# STM32H7RSxx register map
File version: 0.2
CPU: CM7 r0p1, little endian, MPU, FPU, 4 interrupt priority bits
Registers are 32-bit, read-write, reset 0x0 unless marked. A register's access mark holds for its fields unless they carry their own. Offsets are from the block's base; [hi:lo] are bit positions; 'fields as' and 'values as' point back to an identical list; <NAME> marks a mode.

## XSPI1 — XSPI register block
Base 0x52000500
Same registers: XSPI2 0x5200A000, XSPIM 0x5200B400
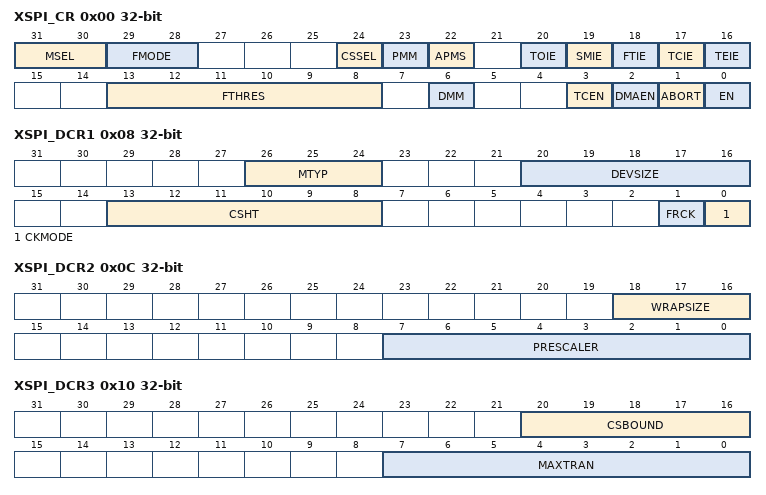
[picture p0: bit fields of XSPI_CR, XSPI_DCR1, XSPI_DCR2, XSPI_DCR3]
0x00 XSPI_CR — XSPI control register
  [31:30] MSEL — Flash select These bits select the memory to be addressed in single-, dual-, quad -or octal-SPI mode in single‑memory configuration (when DMM = 0). - when in quad-SPI mode: - when in octal-SPI mode or dual-quad configuration: 0x: data exchanged over IO[7:0] 1x: data exchanged over IO[15:8] These bits are ignored when in dual-octal configuration (data on 8 bits and DMM = 1) or 16‑bit configuration (data exchanged over IO[15:0]). Note: This bit is mirrored in bit 7. Note: This bitfield can be modified only when BUSY = 0.
    0=data exchanged over IO[3:0]; 1=data exchanged over IO[7:4]; 2=data exchanged over IO[11:8]; 3=data exchanged over IO[15:12]
  [29:28] FMODE — Functional mode This field defines the XSPI functional mode of operation. If DMAEN = 1 already, then the DMA controller for the corresponding channel must be disabled before changing the FMODE[1:0] value. If FMODE[1:0] and FTHRES[4:0] are wrongly updated while DMAEN = 1, the DMA request signal automatically goes to inactive state. Note: This bitfield can be modified only when BUSY = 0.
    0=indirect-write mode; 1=indirect-read mode; 2=automatic status-polling mode; 3=memory-mapped mode
  [24] CSSEL — chip select selection This bit indicates if the XSPI must activate NCS1 or NCS2. Note: This bit can be modified only when BUSY = 0.
    0=NCS1 active; 1=NCS2 active
  [23] PMM — Polling match mode This bit indicates which method must be used to determine a match during the automatic status-polling mode. Note: This bit can be modified only when BUSY = 0.
    0=AND-match mode, SMF is set if all the unmasked bits received from the device match the corresponding bits in the match register; 1=OR-match mode, SMF is set if any of the unmasked bits received from the device matches its corresponding bit in the match register
  [22] APMS — Automatic status-polling mode stop This bit determines if the automatic status-polling is stopped after a match. Note: This bit can be modified only when BUSY = 0.
    0=Automatic status-polling mode is stopped only by abort or by disabling the XSPI; 1=Automatic status-polling mode stops as soon as there is a match
  [20] TOIE — Timeout interrupt enable This bit enables the timeout interrupt.
    0=interrupt disabled; 1=interrupt enabled
  [19] SMIE — Status match interrupt enable This bit enables the status match interrupt.
    0=interrupt disabled; 1=interrupt enabled
  [18] FTIE — FIFO threshold interrupt enable This bit enables the FIFO threshold interrupt.
    0=interrupt disabled; 1=interrupt enabled
  [17] TCIE — Transfer complete interrupt enable This bit enables the transfer complete interrupt.
    0=interrupt disabled; 1=interrupt enabled
  [16] TEIE — Transfer error interrupt enable This bit enables the transfer error interrupt.
    0=interrupt disabled; 1=interrupt enabled
  [13:8] FTHRES — FIFO threshold level This field defines, in indirect mode, the threshold number of bytes in the FIFO that causes the FIFO threshold flag FTF in XSPI_SR, to be set. ... Note: If DMAEN = 1, the DMA controller for the corresponding channel must be disabled before changing the FTHRES[5:0] value.
    0=FTF is set if there are one or more free bytes available to be written to in the FIFO in indirect-write mode, or if there are one or more valid bytes can be read from the FIFO in indirect-read mode; 1=FTF is set if there are two or more free bytes available to be written to in the FIFO in indirect‑write mode, or if there are two or more valid bytes can be read from the FIFO in indirect‑read mode; 63=FTF is set if there are 64 free bytes available to be written to in the FIFO in indirect‑write mode, or if there are 64 valid bytes can be read from the FIFO in indirect‑read mode
  [6] DMM — Dual-memory configuration This bit activates the dual-memory configuration, where two external devices are used simultaneously to double the throughput and the capacity Note: This bit can be modified only when BUSY = 0.
    0=dual-memory configuration disabled; 1=dual-memory configuration enabled
  [3] TCEN — Timeout counter enable This bit is valid only when the memory-mapped mode (FMODE[1:0] = 11) is selected. This bit enables the timeout counter. Note: This bit can be modified only when BUSY = 0.
    0=timeout counter is disabled, and thus the chip-select (NCS) remains active indefinitely after an access in memory-mapped mode; 1=timeout counter is enabled, and thus the chip-select is released in the memory-mapped mode after TIMEOUT[15:0] cycles of external device inactivity
  [2] DMAEN — DMA enable In indirect mode, the DMA can be used to input or output data via XSPI_DR. DMA transfers are initiated when FTF is set. Note: Resetting the DMAEN bit while a DMA transfer is ongoing, breaks the handshake with the DMA. Do not write this bit during DMA operation.
    0=DMA disabled for indirect mode; 1=DMA enabled for indirect mode
  [1] ABORT — Abort request This bit aborts the on-going command sequence. It is automatically reset once the abort is completed. This bit stops the current transfer. Note: This bit is always read as 0.
    0=no abort requested; 1=abort requested
  [0] EN — Enable This bit enables the XSPI. The DMA request can be aborted without having received the ACK in case this EN bit is cleared during the operation. Note: In case this bit is set to 0 during a DMA transfer, the REQ signal to DMA returns to inactive state without waiting for the ACK signal from DMA to be active.
    0=XSPI disabled; 1=XSPI enabled
0x08 XSPI_DCR1 — XSPI device configuration register 1
  [26:24] MTYP — Memory type This bit indicates the type of memory to be supported. Note: In this mode, DQS signal polarity is inverted with respect to the memory clock signal. This is the default value and care must be taken to change MTYP[2:0] for memories different from Micron. Others: Reserved
    0=Micron mode, D0/D1 ordering in DTR 8-data-bit mode. Regular-command protocol in single-, dual-, quad-, and octal-SPI modes.; 1=Macronix mode, D1/D0 ordering in DTR 8-data-bit mode. Regular-command protocol in single-, dual-, quad-, and octal-SPI modes.; 2=Standard mode; 3=Macronix RAM mode, D1/D0 ordering in DTR 8-data-bit mode. Regular-command protocol in single-, dual-, quad-, and octal-SPI modes with dedicated address mapping.; 4=HyperBus memory mode, the protocol follows the HyperBus<sup> </sup>specification. 8-data-bit DTR mode must be selected.; 5=HyperBus register mode, addressing register space. The memory-mapped accesses in this mode must be non-cacheable, or indirect read/write modes must be used.
  [20:16] DEVSIZE — Device size This field defines the size of the external device using the following formula: Number of bytes in device = 2<sup>[DEVSIZE+1]</sup>. DEVSIZE+1 is effectively the number of address bits required to address the external device. The device capacity can be up to 4 Gbytes (addressed using 32-bits) in indirect mode, but the addressable space in memory-mapped mode is limited to 256 Mbytes. In regular-command protocol, if DMM = 1, DEVSIZE[4:0] indicates the total capacity of the two devices together.
  [13:8] CSHT — Chip-select high time CSHT + 1 defines the minimum number of CLK cycles where the chip-select (NCS) must remain high between commands issued to the external device. ...
    0=NCS stays high for at least 1 cycle between external device commands; 1=NCS stays high for at least 2 cycles between external device commands; 63=NCS stays high for at least 64 cycles between external device commands
  [1] FRCK — Free running clock This bit configures the free running clock.
    0=CLK is not free running; 1=CLK is free running (always provided)
  [0] CKMODE — clock mode 0/mode 3 This bit indicates the level taken by the CLK between commands (when NCS = 1).
    0=CLK must stay low while NCS is high (chip-select released), referred to as clock mode 0; 1=CLK must stay high while NCS is high (chip-select released), referred to as clock mode 3
0x0C XSPI_DCR2 — XSPI device configuration register 2
  [18:16] WRAPSIZE — Wrap size This field indicates the wrap size to which the memory is configured. For memories which have a separate command for wrapped instructions, this field indicates the wrap-size associated with the command held in XSPI_WPIR. Others: reserved
    0=wrapped reads are not supported by the memory; 2=external memory supports wrap size of 16 bytes; 3=external memory supports wrap size of 32 bytes; 4=external memory supports wrap size of 64 bytes; 5=external memory supports wrap size of 128 bytes
  [7:0] PRESCALER — Clock prescaler This field defines the scaler factor for generating the CLK based on the kernel clock (value + 1). ... For odd clock division factors, the CLK duty cycle is not 50 %. The clock signal remains low one cycle longer than it stays high. Writing this field automatically starts a new calibration of high-speed interface DLL at the start of next transfer, except in case XSPI_CALOSR or XSPI_CALISR have been written in the meantime. BUSY stays high during the whole calibration execution.
    0=F<sub>CLK</sub> = F<sub>KERNEL</sub>, kernel clock used directly as XSPI CLK (prescaler bypassed). In this case, if the DTR mode is used, it is mandatory to provide to the XSPI a kernel clock that has 50% duty-cycle.; 1=F<sub>CLK</sub> = F<sub>KERNEL</sub>/2
0x10 XSPI_DCR3 — XSPI device configuration register 3
  [20:16] CSBOUND — NCS boundary This field enables the transaction boundary feature. When active, a minimum value of 3 is recommended. The NCS is released on each boundary of 2<sup>CSBOUND</sup> bytes. Others: NCS boundary set to 2<sup>CSBOUND</sup> bytes
    0=NCS boundary disabled
  [7:0] MAXTRAN — Maximum transfer This field enables the communication regulation feature. The NCS is released every MAXTRAN+1 clock cycles when the other XSPI request the access to the bus. Others: maximum communication is set to MAXTRAN + 1 bytes.
    0=maximum communication disabled
0x14 XSPI_DCR4 — XSPI device configuration register 4
  [31:0] REFRESH — Refresh rate This field enables the refresh rate feature. The NCS is released every REFRESH + 1 clock cycles for writes, and REFRESH + 4 clock cycles for reads. Note: These two values can be extended with few clock cycles when refresh occurs during a byte transmission in single-, dual- or quad-SPI mode, because the byte transmission must be completed. Others: maximum communication length is set to REFRESH + 1 clock cycles.
    0=refresh disabled
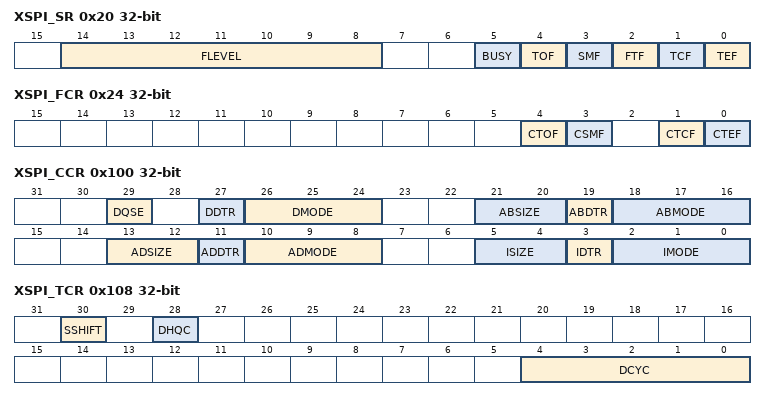
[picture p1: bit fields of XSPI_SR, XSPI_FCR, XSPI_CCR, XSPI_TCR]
0x20 XSPI_SR ro — XSPI status register
  [14:8] FLEVEL — FIFO level This field gives the number of valid bytes that are being held in the FIFO. FLEVEL = 0 when the FIFO is empty, and 64 when it is full. In automatic-status polling mode, FLEVEL is zero.
  [5] BUSY — Busy This bit is set when an operation is ongoing. It is cleared automatically when the operation with the external device is finished and the FIFO is empty.
  [4] TOF — Timeout flag This bit is set when timeout occurs. It is cleared by writing 1 to CTOF.
  [3] SMF — Status match flag This bit is set in automatic status-polling mode when the unmasked received data matches the corresponding bits in the match register (XSPI_PSMAR). It is cleared by writing 1 to CSMF.
  [2] FTF — FIFO threshold flag In indirect mode, this bit is set when the FIFO threshold has been reached, or if there is any data left in the FIFO after the reads from the external device are complete. It is cleared automatically as soon as the threshold condition is no longer true. In automatic status-polling mode this bit is set every time the status register is read, and the bit is cleared when the data register is read.
  [1] TCF — Transfer complete flag This bit is set in indirect mode when the programmed number of data has been transferred or in any mode when the transfer has been aborted.It is cleared by writing 1 to CTCF.
  [0] TEF — Transfer error flag This bit is set in indirect mode when an invalid address is being accessed in indirect mode. It is cleared by writing 1 to CTEF.
0x24 XSPI_FCR wo — XSPI flag clear register
  [4] CTOF — Clear timeout flag Writing 1 clears the TOF flag in the XSPI_SR register.
  [3] CSMF — Clear status match flag Writing 1 clears the SMF flag in the XSPI_SR register.
  [1] CTCF — Clear transfer complete flag Writing 1 clears the TCF flag in the XSPI_SR register.
  [0] CTEF — Clear transfer error flag Writing 1 clears the TEF flag in the XSPI_SR register.
0x40 XSPI_DLR — XSPI data length register
  [31:0] DL — Data length Number of data to be retrieved (value + 1) in indirect and automatic status-polling modes. A value not greater than three (indicating 4 bytes) must be used for automatic status-polling mode. All 1’s in indirect mode means undefined length, where XSPI continues until the end of the memory, as defined by DEVSIZE. 0x0000_0000: 1 byte is to be transferred. 0x0000_0001: 2 bytes are to be transferred. 0x0000_0002: 3 bytes are to be transferred. 0x0000_0003: 4 bytes are to be transferred. ... 0xFFFF_FFFD: 4,294,967,294 (4G-2) bytes are to be transferred. 0xFFFF_FFFE: 4,294,967,295 (4G-1) bytes are to be transferred. 0xFFFF_FFFF: undefined length; all bytes, until the end of the external device, (as defined by DEVSIZE) are to be transferred. Continue reading indefinitely if DEVSIZE = 0x1F. DL[0] is stuck at 1 in dual-memory configuration (DMM = 1) even when 0 is written to this bit, thus assuring that each access transfers an even number of bytes. This field has no effect when in memory-mapped mode.
0x48 XSPI_AR — XSPIaddress register
  [31:0] ADDRESS — Address Address to be sent to the external device. In HyperBus protocol, this field must be even as this protocol is 16-bit word oriented. In dual-memory configuration, AR[0] is forced to 0. Writes to this field are ignored when BUSY = 1 or when FMODE = 11 (memory-mapped mode). Some memory specifications consider that each address corresponds to a 16-bit value. XSPI considers that each address corresponds to an 8-bit value. So the software needs to multiple the address by two when accessing the memory registers.
0x50 XSPI_DR — XSPI data register
  [31:0] DATA — Data Data to be sent/received to/from the external SPI device In indirect-write mode, data written to this register is stored on the FIFO before it is sent to the external device during the data phase. If the FIFO is too full, a write operation is stalled until the FIFO has enough space to accept the amount of data being written. In indirect-read mode, reading this register gives (via the FIFO) the data that was received from the external device. If the FIFO does not have as many bytes as requested by the read operation and if BUSY = 1, the read operation is stalled until enough data is present or until the transfer is complete, whichever happens first. In automatic status-polling mode, this register contains the last data read from the external device (without masking). Word, half-word, and byte accesses to this register are supported. In indirect-write mode, a byte write adds 1 byte to the FIFO, a half-word write 2 bytes, and a word write 4 bytes. Similarly, in indirect-read mode, a byte read removes 1 byte from the FIFO, a halfword read 2 bytes, and a word read 4 bytes. Accesses in indirect mode must be aligned to the bottom of this register: A byte read must read DATA[7:0] and a half-word read must read DATA[15:0].
0x80 XSPI_PSMKR — XSPI polling status mask register
  [31:0] MASK — Status mask Mask to be applied to the status bytes received in automatic status-polling mode For bit n:
    0=bit n of the data received in automatic status-polling mode is masked and its value is not considered in the matching logic; 1=bit n of the data received in automatic status-polling mode is unmasked and its value is considered in the matching logic
0x88 XSPI_PSMAR — XSPI polling status match register
  [31:0] MATCH — Status match Value to be compared with the masked status register to get a match
0x90 XSPI_PIR — XSPI polling interval register
  [15:0] INTERVAL — Polling interval Number of CLK cycle between a read during the automatic status-polling phases
0x100 XSPI_CCR — XSPI communication configuration register
  [29] DQSE — DQS enable This bit enables the data strobe management.
    0=DQS disabled; 1=DQS enabled
  [27] DDTR — Data double transfer rate This bit sets the DTR mode for the data phase.
    0=DTR mode disabled for data phase; 1=DTR mode enabled for data phase
  [26:24] DMODE — Data mode This field defines the data phase mode of operation. Others: reserved
    0=no data; 1=data on a single line; 2=data on two lines; 3=data on four lines; 4=data on eight lines; 5=data on 16 lines
  [21:20] ABSIZE — Alternate bytes size This bit defines alternate bytes size.
    0=8-bit alternate bytes; 1=16-bit alternate bytes; 2=24-bit alternate bytes; 3=32-bit alternate bytes
  [19] ABDTR — Alternate bytes double transfer rate This bit sets the DTR mode for the alternate bytes phase. Note: This field can be written only when BUSY = 0.
    0=DTR mode disabled for alternate bytes phase; 1=DTR mode enabled for alternate bytes phase
  [18:16] ABMODE — Alternate-byte mode This field defines the alternate byte phase mode of operation. Others: reserved
    0=no alternate bytes; 1=alternate bytes on a single line; 2=alternate bytes on two lines; 3=alternate bytes on four lines
  [13:12] ADSIZE — Address size This field defines address size.
    0=8-bit address; 1=16-bit address; 2=24-bit address; 3=32-bit address
  [11] ADDTR — Address double transfer rate This bit sets the DTR mode for the address phase.
    0=DTR mode disabled for address phase; 1=DTR mode enabled for address phase
  [10:8] ADMODE — Address mode This field defines the address phase mode of operation. Others: reserved
    0=no address; 1=address on a single line; 2=address on two lines; 3=address on four lines; 4=address on eight lines
  [5:4] ISIZE — Instruction size This bit defines instruction size.
    0=8-bit instruction; 1=16-bit instruction; 2=24-bit instruction; 3=32-bit instruction
  [3] IDTR — Instruction double transfer rate This bit sets the DTR mode for the instruction phase.
    0=DTR mode disabled for instruction phase; 1=DTR mode enabled for instruction phase
  [2:0] IMODE — Instruction mode This field defines the instruction phase mode of operation. Others: reserved
    0=no instruction; 1=instruction on a single line; 2=instruction on two lines; 3=instruction on four lines; 4=instruction on eight lines
0x108 XSPI_TCR — XSPI timing configuration register
  [30] SSHIFT — Sample shift By default, the XSPI samples data 1/2 of a CLK cycle after the data is driven by the external device. This bit allows the data to be sampled later in order to consider the external signal delays. The software must ensure that SSHIFT = 0 when the data phase is configured in DTR mode (when DDTR = 1.)
    0=no shift; 1=1/2 cycle shift
  [28] DHQC — Delay hold quarter cycle
    0=no delay hold; 1=1/4 cycle hold
  [4:0] DCYC — Number of dummy cycles This field defines the duration of the dummy phase. In both SDR and DTR modes, it specifies a number of CLK cycles (0-31).
0x110 XSPI_IR — XSPI instruction register
  [31:0] INSTRUCTION — Instruction Instruction to be sent to the external SPI device
0x120 XSPI_ABR — XSPI alternate bytes register
  [31:0] ALTERNATE — Alternate bytes Optional data to be sent to the external SPI device right after the address.
0x130 XSPI_LPTR — XSPI low-power timeout register
  [15:0] TIMEOUT — Timeout period After each access in memory-mapped mode, the XSPI prefetches the subsequent bytes and hold them in the FIFO. This field indicates how many CLK cycles the XSPI waits after the clock becomes inactive and until it raises the NCS, putting the external device in a lower-consumption state.
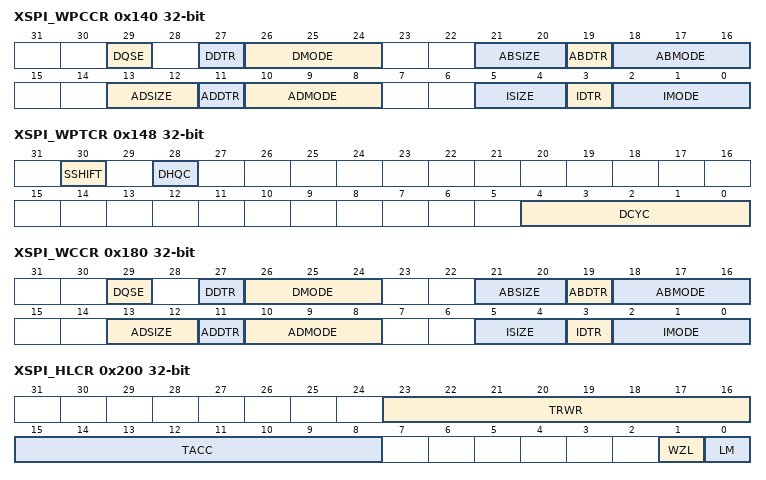
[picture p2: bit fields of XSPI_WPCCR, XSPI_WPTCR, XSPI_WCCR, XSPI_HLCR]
0x140 XSPI_WPCCR — XSPI wrap communication configuration register
  [29] DQSE — DQS enable This bit enables the data strobe management.
    0=DQS disabled; 1=DQS enabled
  [27] DDTR — Data double transfer rate This bit sets the DTR mode for the data phase.
    values as XSPI_CCR.DDTR
  [26:24] DMODE — Data mode This field defines the data phase mode of operation. 101; data on 16 lines Others: reserved
    0=no data; 1=data on a single line; 2=data on two lines; 3=data on four lines; 4=data on eight lines
  [21:20] ABSIZE — Alternate bytes size This bit defines alternate bytes size.
    values as XSPI_CCR.ABSIZE
  [19] ABDTR — Alternate bytes double transfer rate This bit sets the DTR mode for the alternate bytes phase.
    values as XSPI_CCR.ABDTR
  [18:16] ABMODE — Alternate-byte mode This field defines the alternate byte phase mode of operation.
    0=no alternate bytes; 1=alternate bytes on a single line; 2=alternate bytes on two lines; 3=alternate bytes on four lines; 4=alternate bytes on eight lines; 5=alternate bytes on 16 lines
  [13:12] ADSIZE — Address size This field defines address size.
    values as XSPI_CCR.ADSIZE
  [11] ADDTR — Address double transfer rate This bit sets the DTR mode for the address phase.
    values as XSPI_CCR.ADDTR
  [10:8] ADMODE — Address mode This field defines the address phase mode of operation. Others: reserved
    values as XSPI_CCR.ADMODE
  [5:4] ISIZE — Instruction size This field defines instruction size.
    values as XSPI_CCR.ISIZE
  [3] IDTR — Instruction double transfer rate This bit sets the DTR mode for the instruction phase.
    values as XSPI_CCR.IDTR
  [2:0] IMODE — Instruction mode This field defines the instruction phase mode of operation. Others: reserved
    values as XSPI_CCR.IMODE
0x148 XSPI_WPTCR — XSPI wrap timing configuration register
  [30] SSHIFT — Sample shift By default, the XSPI samples data 1/2 of a CLK cycle after the data is driven by the external device. This bit allows the data to be sampled later in order to consider the external signal delays. The firmware must assure that SSHIFT=0 when the data phase is configured in DTR mode (when DDTR = 1).
    0=no shift; 1=1/2 cycle shift
  [28] DHQC — Delay hold quarter cycle Add a quarter cycle delay on the outputs in DTR communication to match hold requirement.
    0=no quarter cycle delay; 1=quarter cycle delay inserted
  [4:0] DCYC — Number of dummy cycles This field defines the duration of the dummy phase. In both SDR and DTR modes, it specifies a number of CLK cycles (0-31).
0x150 XSPI_WPIR — XSPI wrap instruction register
  fields as XSPI_IR
0x160 XSPI_WPABR — XSPI wrap alternate byte register
  [31:0] ALTERNATE — Alternate bytes Optional data to be sent to the external SPI device right after the address
0x180 XSPI_WCCR — XSPI write communication configuration register
  [29] DQSE — DQS enable This bit enables the data strobe management.
    0=DQS disabled; 1=DQS enabled
  [27] DDTR — data double transfer rate This bit sets the DTR mode for the data phase.
    values as XSPI_CCR.DDTR
  [26:24] DMODE — Data mode This field defines the data phase mode of operation.
    0=no data; 1=data on a single line; 2=data on two lines; 3=data on four lines; 4=data on eight lines; 5=Data on 16 lines
  [21:20] ABSIZE — Alternate bytes size This field defines alternate bytes size:
    values as XSPI_CCR.ABSIZE
  [19] ABDTR — Alternate bytes double-transfer rate This bit sets the DTR mode for the alternate-bytes phase.
    0=DTR mode disabled for alternate-bytes phase; 1=DTR mode enabled for alternate-bytes phase
  [18:16] ABMODE — Alternate-byte mode This field defines the alternate-byte phase mode of operation. Others: reserved
    0=no alternate bytes; 1=alternate bytes on a single line; 2=alternate bytes on two lines; 3=alternate bytes on four lines; 4=alternate bytes on eight lines
  [13:12] ADSIZE — Address size This field defines address size.
    values as XSPI_CCR.ADSIZE
  [11] ADDTR — Address double transfer rate This bit sets the DTR mode for the address phase.
    values as XSPI_CCR.ADDTR
  [10:8] ADMODE — Address mode This field defines the address phase mode of operation. Others: reserved
    values as XSPI_CCR.ADMODE
  [5:4] ISIZE — Instruction size This bit defines instruction size:
    values as XSPI_CCR.ISIZE
  [3] IDTR — Instruction double transfer rate This bit sets the DTR mode for the instruction phase.
    values as XSPI_CCR.IDTR
  [2:0] IMODE — Instruction mode This field defines the instruction phase mode of operation. Others: reserved
    values as XSPI_CCR.IMODE
0x188 XSPI_WTCR — XSPI write timing configuration register
  [4:0] DCYC — Number of dummy cycles This field defines the duration of the dummy phase. In both SDR and DTR modes, it specifies a number of CLK cycles (0-31). It is recommended to have at least 5 dummy cycles when using memories with DQS activated.
0x190 XSPI_WIR — XSPI write instruction register
  fields as XSPI_IR
0x1A0 XSPI_WABR — XSPI write alternate byte register
  fields as XSPI_WPABR
0x200 XSPI_HLCR — XSPI HyperBus latency configuration register
  [23:16] TRWR — Read write recovery time Device read write recovery time expressed in number of communication clock cycles
  [15:8] TACC — Access time Device access time expressed in number of communication clock cycles
  [1] WZL — Write zero latency This bit enables zero latency on write operations.
    0=latency on write accesses; 1=no latency on write accesses
  [0] LM — Latency mode This bit selects the Latency mode. Note: This bit must be set when using the dual-octal HyperBus configuration.
    0=Variable initial latency; 1=Fixed latency
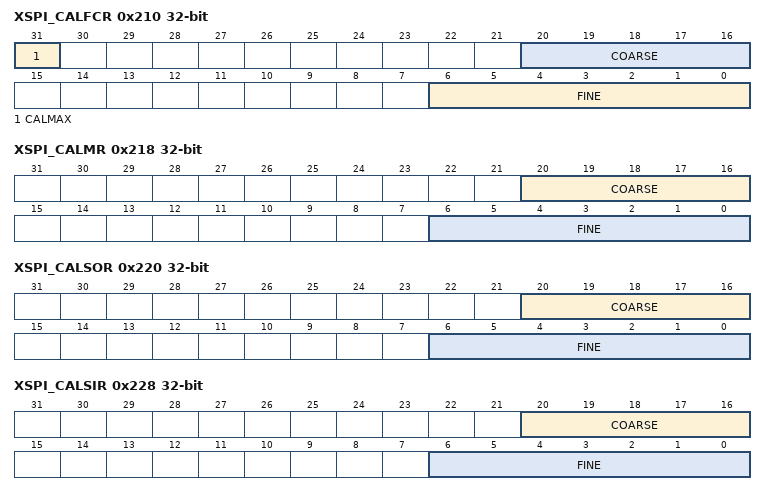
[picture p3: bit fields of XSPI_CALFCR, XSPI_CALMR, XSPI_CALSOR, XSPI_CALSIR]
0x210 XSPI_CALFCR ro — XSPI full-cycle calibration configuration
  [31] CALMAX — Max value This bit gets set when the memory-clock period is outside the range of DLL master, in which case XSPI_CALFCR and XSPI_CALSR are updated with the values for the maximum delay.
  [20:16] COARSE — Coarse calibration The unitary value of delay for this field depends on product technology (refer to the product datasheet).
  [6:0] FINE — Fine calibration The unitary value of delay for this field depends on product technology (refer to the product datasheet).
0x218 XSPI_CALMR — XSPI DLL master calibration configuration
  [20:16] COARSE — Coarse calibration The unitary value of delay for this field depends on product technology (refer to the product datasheet).
  [6:0] FINE — Fine calibration The unitary value of delay for this field depends on product technology (refer to the product datasheet).
0x220 XSPI_CALSOR — XSPI DLL slave output calibration configuration
  fields as XSPI_CALMR
0x228 XSPI_CALSIR — XSPI DLL slave input calibration configuration
  fields as XSPI_CALMR
